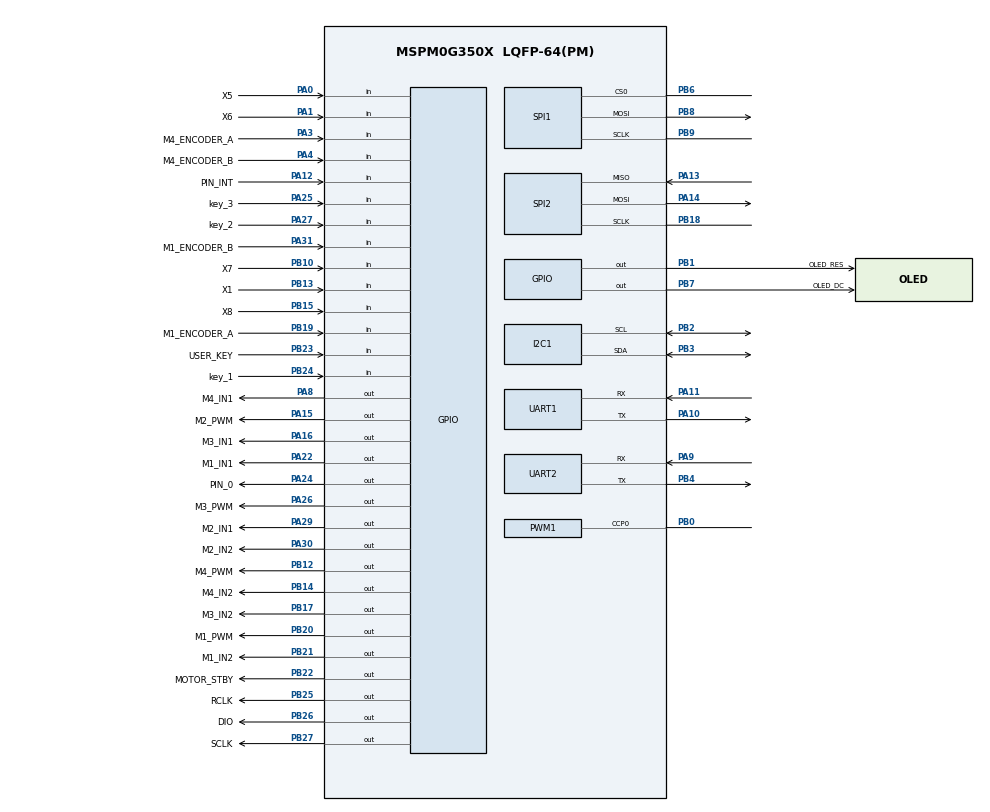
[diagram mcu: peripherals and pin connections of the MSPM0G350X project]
/**
 * @cliArgs --device "MSPM0G350X" --part "Default" --package "LQFP-64(PM)" --product "mspm0_sdk@2.10.00.04"
 * @versions {"tool":"1.27.1+4634"}
 */

/**
 * Import the modules used in this configuration.
 */
const GPIO   = scripting.addModule("/ti/driverlib/GPIO", {}, false);
const GPIO1  = GPIO.addInstance();
const GPIO2  = GPIO.addInstance();
const GPIO3  = GPIO.addInstance();
const GPIO4  = GPIO.addInstance();
const GPIO5  = GPIO.addInstance();
const GPIO6  = GPIO.addInstance();
const GPIO7  = GPIO.addInstance();
const GPIO8  = GPIO.addInstance();
const GPIO9  = GPIO.addInstance();
const GPIO10 = GPIO.addInstance();
const I2C    = scripting.addModule("/ti/driverlib/I2C", {}, false);
const I2C1   = I2C.addInstance();
const PWM    = scripting.addModule("/ti/driverlib/PWM", {}, false);
const PWM1   = PWM.addInstance();
const SPI    = scripting.addModule("/ti/driverlib/SPI", {}, false);
const SPI1   = SPI.addInstance();
const SPI2   = SPI.addInstance();
const SYSCTL = scripting.addModule("/ti/driverlib/SYSCTL");
const UART   = scripting.addModule("/ti/driverlib/UART", {}, false);
const UART1  = UART.addInstance();
const UART2  = UART.addInstance();

/**
 * Write custom configuration values to the imported modules.
 */
GPIO1.$name                         = "GPIO_GRP_LINE";
GPIO1.associatedPins.create(8);
GPIO1.associatedPins[0].$name       = "X2";
GPIO1.associatedPins[0].direction   = "INPUT";
GPIO1.associatedPins[1].$name       = "X3";
GPIO1.associatedPins[1].direction   = "INPUT";
GPIO1.associatedPins[2].$name       = "X4";
GPIO1.associatedPins[2].direction   = "INPUT";
GPIO1.associatedPins[3].direction   = "INPUT";
GPIO1.associatedPins[3].$name       = "X5";
GPIO1.associatedPins[3].pin.$assign = "PA0";
GPIO1.associatedPins[4].$name       = "X6";
GPIO1.associatedPins[4].direction   = "INPUT";
GPIO1.associatedPins[4].pin.$assign = "PA1";
GPIO1.associatedPins[5].$name       = "X7";
GPIO1.associatedPins[5].direction   = "INPUT";
GPIO1.associatedPins[5].pin.$assign = "PB10";
GPIO1.associatedPins[6].direction   = "INPUT";
GPIO1.associatedPins[6].$name       = "X8";
GPIO1.associatedPins[6].pin.$assign = "PB15";
GPIO1.associatedPins[7].direction   = "INPUT";
GPIO1.associatedPins[7].$name       = "X1";
GPIO1.associatedPins[7].pin.$assign = "PB13";

const Board = scripting.addModule("/ti/driverlib/Board", {}, false);

GPIO2.$name                         = "GPIO_GRP_MOTOR_L";
GPIO2.associatedPins.create(7);
GPIO2.associatedPins[0].$name       = "M1_PWM";
GPIO2.associatedPins[0].ioStructure = "SD";
GPIO2.associatedPins[0].pin.$assign = "PB20";
GPIO2.associatedPins[1].$name       = "M1_IN1";
GPIO2.associatedPins[1].ioStructure = "SD";
GPIO2.associatedPins[1].pin.$assign = "PA22";
GPIO2.associatedPins[2].$name       = "M1_IN2";
GPIO2.associatedPins[2].ioStructure = "SD";
GPIO2.associatedPins[2].pin.$assign = "PB21";
GPIO2.associatedPins[3].$name       = "M2_PWM";
GPIO2.associatedPins[3].ioStructure = "SD";
GPIO2.associatedPins[3].pin.$assign = "PA15";
GPIO2.associatedPins[4].$name       = "M2_IN1";
GPIO2.associatedPins[4].ioStructure = "SD";
GPIO2.associatedPins[4].pin.$assign = "PA29";
GPIO2.associatedPins[5].$name       = "M2_IN2";
GPIO2.associatedPins[5].ioStructure = "SD";
GPIO2.associatedPins[5].pin.$assign = "PA30";
GPIO2.associatedPins[6].ioStructure = "SD";
GPIO2.associatedPins[6].$name       = "MOTOR_STBY";
GPIO2.associatedPins[6].pin.$assign = "PB22";

GPIO3.$name                         = "GPIO_GRP_MOTOR_R";
GPIO3.associatedPins.create(6);
GPIO3.associatedPins[0].ioStructure = "SD";
GPIO3.associatedPins[0].$name       = "M3_PWM";
GPIO3.associatedPins[0].pin.$assign = "PA26";
GPIO3.associatedPins[1].$name       = "M3_IN1";
GPIO3.associatedPins[1].ioStructure = "SD";
GPIO3.associatedPins[1].pin.$assign = "PA16";
GPIO3.associatedPins[2].$name       = "M3_IN2";
GPIO3.associatedPins[2].ioStructure = "SD";
GPIO3.associatedPins[2].pin.$assign = "PB17";
GPIO3.associatedPins[3].$name       = "M4_PWM";
GPIO3.associatedPins[3].ioStructure = "SD";
GPIO3.associatedPins[3].pin.$assign = "PB12";
GPIO3.associatedPins[4].$name       = "M4_IN1";
GPIO3.associatedPins[4].ioStructure = "SD";
GPIO3.associatedPins[4].pin.$assign = "PA8";
GPIO3.associatedPins[5].$name       = "M4_IN2";
GPIO3.associatedPins[5].ioStructure = "SD";
GPIO3.associatedPins[5].pin.$assign = "PB14";

GPIO4.$name                                 = "GPIO_BUTTON";
GPIO4.associatedPins[0].$name               = "USER_KEY";
GPIO4.associatedPins[0].internalResistor    = "PULL_UP";
GPIO4.associatedPins[0].direction           = "INPUT";
GPIO4.associatedPins[0].assignedPortSegment = "Upper";
GPIO4.associatedPins[0].assignedPort        = "PORTB";
GPIO4.associatedPins[0].assignedPin         = "23";
GPIO4.associatedPins[0].pin.$assign         = "PB23";

GPIO5.$name                               = "GPIO_MPU6050";
GPIO5.associatedPins[0].$name             = "PIN_INT";
GPIO5.associatedPins[0].direction         = "INPUT";
GPIO5.associatedPins[0].internalResistor  = "PULL_UP";
GPIO5.associatedPins[0].interruptEn       = true;
GPIO5.associatedPins[0].interruptPriority = "1";
GPIO5.associatedPins[0].polarity          = "FALL";
GPIO5.associatedPins[0].pin.$assign       = "PA12";

GPIO6.$name                          = "GPIO_OLED";
GPIO6.associatedPins.create(2);
GPIO6.associatedPins[0].ioStructure  = "SD";
GPIO6.associatedPins[0].initialValue = "SET";
GPIO6.associatedPins[0].$name        = "OLED_RES";
GPIO6.associatedPins[0].pin.$assign  = "PB1";
GPIO6.associatedPins[1].$name        = "OLED_DC";
GPIO6.associatedPins[1].pin.$assign  = "PB7";

GPIO7.$name                               = "GPIO_GRP_ENCODER";
GPIO7.associatedPins.create(4);
GPIO7.associatedPins[0].$name             = "M1_ENCODER_A";
GPIO7.associatedPins[0].direction         = "INPUT";
GPIO7.associatedPins[0].internalResistor  = "PULL_UP";
GPIO7.associatedPins[0].interruptEn       = true;
GPIO7.associatedPins[0].interruptPriority = "1";
GPIO7.associatedPins[0].polarity          = "RISE_FALL";
GPIO7.associatedPins[0].pin.$assign       = "PB19";
GPIO7.associatedPins[1].direction         = "INPUT";
GPIO7.associatedPins[1].internalResistor  = "PULL_UP";
GPIO7.associatedPins[1].interruptEn       = true;
GPIO7.associatedPins[1].interruptPriority = "1";
GPIO7.associatedPins[1].polarity          = "RISE_FALL";
GPIO7.associatedPins[1].$name             = "M1_ENCODER_B";
GPIO7.associatedPins[1].pin.$assign       = "PA31";
GPIO7.associatedPins[2].$name             = "M4_ENCODER_A";
GPIO7.associatedPins[2].direction         = "INPUT";
GPIO7.associatedPins[2].internalResistor  = "PULL_UP";
GPIO7.associatedPins[2].interruptEn       = true;
GPIO7.associatedPins[2].interruptPriority = "1";
GPIO7.associatedPins[2].polarity          = "RISE_FALL";
GPIO7.associatedPins[2].pin.$assign       = "PA3";
GPIO7.associatedPins[3].$name             = "M4_ENCODER_B";
GPIO7.associatedPins[3].direction         = "INPUT";
GPIO7.associatedPins[3].internalResistor  = "PULL_UP";
GPIO7.associatedPins[3].pin.$assign       = "PA4";

GPIO8.$name                         = "number";
GPIO8.associatedPins.create(3);
GPIO8.associatedPins[0].$name       = "SCLK";
GPIO8.associatedPins[0].pin.$assign = "PB27";
GPIO8.associatedPins[1].$name       = "RCLK";
GPIO8.associatedPins[1].pin.$assign = "PB25";
GPIO8.associatedPins[2].$name       = "DIO";
GPIO8.associatedPins[2].pin.$assign = "PB26";

GPIO9.$name                         = "Electromagnet";
GPIO9.associatedPins[0].$name       = "PIN_0";
GPIO9.associatedPins[0].pin.$assign = "PA24";

GPIO10.$name                                 = "KEY";
GPIO10.associatedPins.create(3);
GPIO10.associatedPins[0].$name               = "key_1";
GPIO10.associatedPins[0].assignedPortSegment = "Upper";
GPIO10.associatedPins[0].direction           = "INPUT";
GPIO10.associatedPins[0].internalResistor    = "PULL_UP";
GPIO10.associatedPins[0].pin.$assign         = "PB24";
GPIO10.associatedPins[1].$name               = "key_2";
GPIO10.associatedPins[1].assignedPortSegment = "Upper";
GPIO10.associatedPins[1].direction           = "INPUT";
GPIO10.associatedPins[1].internalResistor    = "PULL_UP";
GPIO10.associatedPins[1].pin.$assign         = "PA27";
GPIO10.associatedPins[2].$name               = "key_3";
GPIO10.associatedPins[2].assignedPortSegment = "Upper";
GPIO10.associatedPins[2].direction           = "INPUT";
GPIO10.associatedPins[2].internalResistor    = "PULL_UP";
GPIO10.associatedPins[2].pin.$assign         = "PA25";

I2C1.basicEnableController             = true;
I2C1.$name                             = "I2C_MPU6050";
I2C1.basicControllerStandardBusSpeed   = "Fast";
I2C1.peripheral.$assign                = "I2C1";
I2C1.peripheral.sdaPin.$assign         = "PB3";
I2C1.peripheral.sclPin.$assign         = "PB2";
I2C1.sdaPinConfig.hideOutputInversion  = scripting.forceWrite(false);
I2C1.sdaPinConfig.onlyInternalResistor = scripting.forceWrite(false);
I2C1.sdaPinConfig.passedPeripheralType = scripting.forceWrite("Digital");
I2C1.sdaPinConfig.$name                = "ti_driverlib_gpio_GPIOPinGeneric4";
I2C1.sclPinConfig.hideOutputInversion  = scripting.forceWrite(false);
I2C1.sclPinConfig.onlyInternalResistor = scripting.forceWrite(false);
I2C1.sclPinConfig.passedPeripheralType = scripting.forceWrite("Digital");
I2C1.sclPinConfig.$name                = "ti_driverlib_gpio_GPIOPinGeneric5";

PWM1.$name                              = "RGB_PWM";
PWM1.interrupts                         = ["LOAD_EVENT"];
PWM1.ccIndex                            = [0];
PWM1.timerCount                         = 100;
PWM1.PWM_CHANNEL_0.$name                = "ti_driverlib_pwm_PWMTimerCC0";
PWM1.PWM_CHANNEL_0.initVal              = "HIGH";
PWM1.ccp0PinConfig.$name                = "ti_driverlib_gpio_GPIOPinGeneric2";
PWM1.ccp0PinConfig.direction            = scripting.forceWrite("OUTPUT");
PWM1.ccp0PinConfig.hideOutputInversion  = scripting.forceWrite(false);
PWM1.ccp0PinConfig.onlyInternalResistor = scripting.forceWrite(false);
PWM1.ccp0PinConfig.passedPeripheralType = scripting.forceWrite("Digital");
PWM1.ccp0PinConfig.enableConfig         = true;
PWM1.peripheral.ccp0Pin.$assign         = "PB0";

SPI1.$name                      = "SPI_0";
SPI1.direction                  = "PICO";
SPI1.sclkPinConfig.$name        = "ti_driverlib_gpio_GPIOPinGeneric0";
SPI1.mosiPinConfig.$name        = "ti_driverlib_gpio_GPIOPinGeneric1";
SPI1.cs0PinConfig.$name         = "ti_driverlib_gpio_GPIOPinGeneric3";
SPI1.peripheral.$assign         = "SPI1";
SPI1.peripheral.sclkPin.$assign = "PB9";
SPI1.peripheral.mosiPin.$assign = "PB8";
SPI1.peripheral.cs0Pin.$assign  = "PB6";

SPI2.$name                              = "SPI_1";
SPI2.mode                               = "PERIPHERAL";
SPI2.frameFormat                        = "MOTO3";
SPI2.sclkPinConfig.onlyInternalResistor = scripting.forceWrite(false);
SPI2.sclkPinConfig.passedPeripheralType = scripting.forceWrite("Digital");
SPI2.sclkPinConfig.$name                = "ti_driverlib_gpio_GPIOPinGeneric10";
SPI2.mosiPinConfig.hideOutputInversion  = scripting.forceWrite(false);
SPI2.mosiPinConfig.onlyInternalResistor = scripting.forceWrite(false);
SPI2.mosiPinConfig.passedPeripheralType = scripting.forceWrite("Digital");
SPI2.mosiPinConfig.$name                = "ti_driverlib_gpio_GPIOPinGeneric11";
SPI2.misoPinConfig.onlyInternalResistor = scripting.forceWrite(false);
SPI2.misoPinConfig.passedPeripheralType = scripting.forceWrite("Digital");
SPI2.misoPinConfig.$name                = "ti_driverlib_gpio_GPIOPinGeneric12";
SPI2.peripheral.sclkPin.$assign         = "PB18";
SPI2.peripheral.mosiPin.$assign         = "PA14";
SPI2.peripheral.misoPin.$assign         = "PA13";

SYSCTL.HFCLKSource   = "HFXT";
SYSCTL.SYSPLL_CLK0En = true;
SYSCTL.MCLKSource    = "HSCLK";
SYSCTL.HFCLK_Freq    = 40000000;

UART1.$name                    = "UART_0";
UART1.targetBaudRate           = 115200;
UART1.enabledInterrupts        = ["RX"];
UART1.peripheral.rxPin.$assign = "PA11";
UART1.peripheral.txPin.$assign = "PA10";
UART1.txPinConfig.$name        = "ti_driverlib_gpio_GPIOPinGeneric6";
UART1.rxPinConfig.$name        = "ti_driverlib_gpio_GPIOPinGeneric7";

UART2.$name                            = "Bluetooth_UART_1";
UART2.targetBaudRate                   = 115200;
UART2.peripheral.rxPin.$assign         = "PA9";
UART2.peripheral.txPin.$assign         = "PB4";
UART2.txPinConfig.direction            = scripting.forceWrite("OUTPUT");
UART2.txPinConfig.hideOutputInversion  = scripting.forceWrite(false);
UART2.txPinConfig.onlyInternalResistor = scripting.forceWrite(false);
UART2.txPinConfig.passedPeripheralType = scripting.forceWrite("Digital");
UART2.txPinConfig.$name                = "ti_driverlib_gpio_GPIOPinGeneric8";
UART2.rxPinConfig.hideOutputInversion  = scripting.forceWrite(false);
UART2.rxPinConfig.onlyInternalResistor = scripting.forceWrite(false);
UART2.rxPinConfig.passedPeripheralType = scripting.forceWrite("Digital");
UART2.rxPinConfig.$name                = "ti_driverlib_gpio_GPIOPinGeneric9";

/**
 * Pinmux solution for unlocked pins/peripherals. This ensures that minor changes to the automatic solver in a future
 * version of the tool will not impact the pinmux you originally saw.  These lines can be completely deleted in order to
 * re-solve from scratch.
 */
GPIO1.associatedPins[0].pin.$suggestSolution = "PB16";
GPIO1.associatedPins[1].pin.$suggestSolution = "PA17";
GPIO1.associatedPins[2].pin.$suggestSolution = "PA18";
Board.peripheral.$suggestSolution            = "DEBUGSS";
Board.peripheral.swclkPin.$suggestSolution   = "PA20";
Board.peripheral.swdioPin.$suggestSolution   = "PA19";
PWM1.peripheral.$suggestSolution             = "TIMA1";
SPI2.peripheral.$suggestSolution             = "SPI0";
SYSCTL.peripheral.$suggestSolution           = "SYSCTL";
UART1.peripheral.$suggestSolution            = "UART0";
UART2.peripheral.$suggestSolution            = "UART1";
